VERSION ""

NS_ :

BS_:

BU_: VCU CIM BMS
VAL_TABLE_ KeyMatched 1 "Correct Key" 0 "Incorrect Key" ;
VAL_TABLE_ ClearFault 1 "Clear Fault Command" 0 "NA" ;

BO_ 274 BMS_HV_12: 8 BMS
 SG_ nBatteryHV12Multiplexor M : 0|3@1+ (1,0) [0|7] ""  VCU
 SG_ Batt_SerialNumber m1 : 56|8@1+ (1,0) [0|255] ""  VCU
 SG_ BMS_Calibration_info m0 : 32|8@1+ (1,0) [0|255] ""  VCU
 SG_ BMS_Software_info m0 : 24|8@1+ (1,0) [0|255] ""  VCU

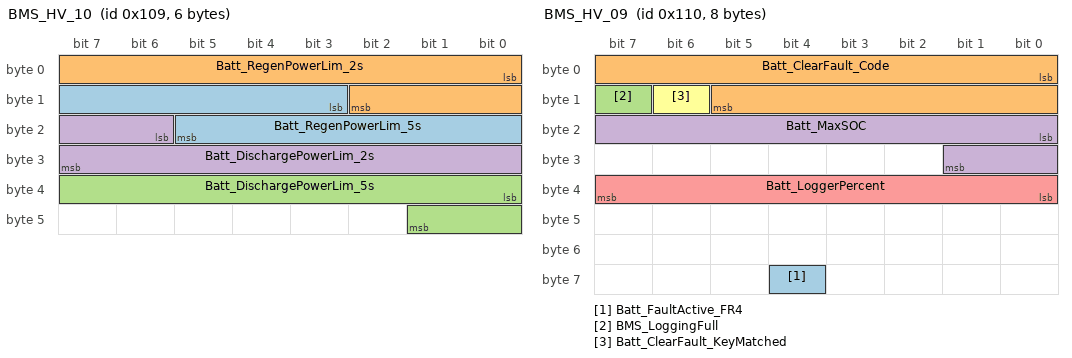
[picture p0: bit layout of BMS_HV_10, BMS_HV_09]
BO_ 265 BMS_HV_10: 6 BMS
 SG_ Batt_RegenPowerLim_5s : 11|11@1+ (0.5,0) [0|1023.5] "kW"  VCU
 SG_ Batt_RegenPowerLim_2s : 0|11@1+ (0.5,0) [0|1023.5] "kW"  VCU
 SG_ Batt_DischargePowerLim_5s : 32|10@1+ (0.5,-511.5) [-511.5|0] "kW"  VCU
 SG_ Batt_DischargePowerLim_2s : 22|10@1+ (0.5,-511.5) [-511.5|0] "kW"  VCU

BO_ 272 BMS_HV_09: 8 BMS
 SG_ Batt_FaultActive_FR4 : 60|1@1+ (1,0) [0|1] ""  VCU
 SG_ Batt_ClearFault_Code : 0|14@1+ (1,0) [0|9999] ""  VCU
 SG_ BMS_LoggingFull : 15|1@1+ (1,0) [0|1] ""  VCU
 SG_ Batt_MaxSOC : 16|10@1+ (0.1,0) [0|102.3] "%"  VCU
 SG_ Batt_LoggerPercent : 32|8@1+ (0.5,0) [0|127.5] "%"  VCU
 SG_ Batt_ClearFault_KeyMatched : 14|1@1+ (1,0) [0|1] ""  VCU

BO_ 264 VCM_FaultClearing: 8 VCU
 SG_ VCM_ClearBattFault_Key : 8|14@1+ (1,0) [0|9999] ""  BMS
 SG_ VCM_ClearBattFault_B : 0|1@1+ (1,0) [0|1] ""  BMS

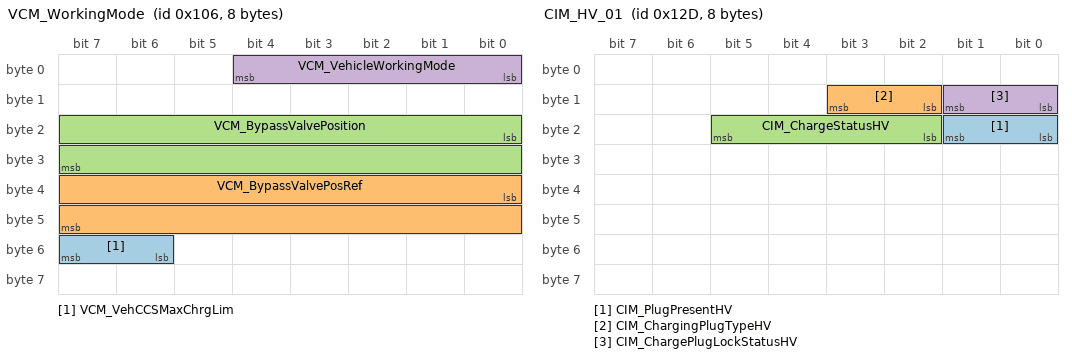
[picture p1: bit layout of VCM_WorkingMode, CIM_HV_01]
BO_ 262 VCM_WorkingMode: 8 VCU
 SG_ VCM_VehCCSMaxChrgLim : 54|2@1+ (1,0) [0|3] ""  BMS
 SG_ VCM_BypassValvePosRef : 32|16@1+ (0.1,0) [0|1000] "%"  BMS
 SG_ VCM_BypassValvePosition : 16|16@1+ (0.1,0) [0|1000] "%"  BMS
 SG_ VCM_VehicleWorkingMode : 0|5@1+ (1,0) [0|31] ""  BMS

BO_ 1537 BMS_CCP_TX: 8 BMS

BO_ 1536 BMS_CCP_RX: 8 BMS

BO_ 301 CIM_HV_01: 8 CIM
 SG_ CIM_PlugPresentHV : 16|2@1+ (1,0) [0|3] ""  BMS,VCU
 SG_ CIM_ChargingPlugTypeHV : 10|2@1+ (1,0) [0|3] ""  BMS,VCU
 SG_ CIM_ChargeStatusHV : 18|4@1+ (1,0) [0|15] ""  BMS,VCU
 SG_ CIM_ChargePlugLockStatusHV : 8|2@1+ (1,0) [0|3] ""  BMS,VCU

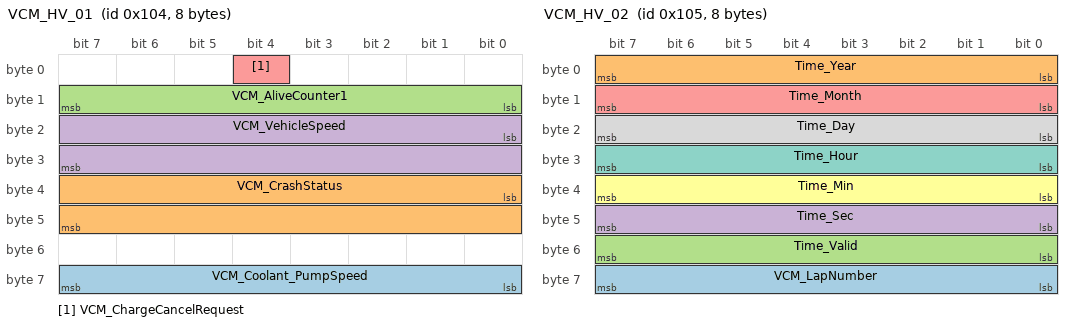
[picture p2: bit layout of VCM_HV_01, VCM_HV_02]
BO_ 260 VCM_HV_01: 8 VCU
 SG_ VCM_Coolant_PumpSpeed : 56|8@1+ (100,0) [0|25500] "RPM"  BMS
 SG_ VCM_CrashStatus : 32|16@1+ (1,0) [0|65535] ""  BMS
 SG_ VCM_AliveCounter1 : 8|8@1+ (1,0) [0|255] ""  BMS
 SG_ VCM_VehicleSpeed : 16|16@1+ (1,-32768) [-32768|32767] "kph"  BMS
 SG_ VCM_ChargeCancelRequest : 4|1@1+ (1,0) [0|1] ""  BMS

BO_ 261 VCM_HV_02: 8 VCU
 SG_ VCM_LapNumber : 56|8@1+ (1,0) [0|255] ""  BMS
 SG_ Time_Year : 0|8@1+ (1,0) [0|255] "min"  BMS
 SG_ Time_Valid : 48|8@1+ (1,0) [0|255] "min"  BMS
 SG_ Time_Sec : 40|8@1+ (1,0) [0|255] "min"  BMS
 SG_ Time_Month : 8|8@1+ (1,0) [0|255] "min"  BMS
 SG_ Time_Min : 32|8@1+ (1,0) [0|255] "min"  BMS
 SG_ Time_Hour : 24|8@1+ (1,0) [0|255] "min"  BMS
 SG_ Time_Day : 16|8@1+ (1,0) [0|255] "min"  BMS

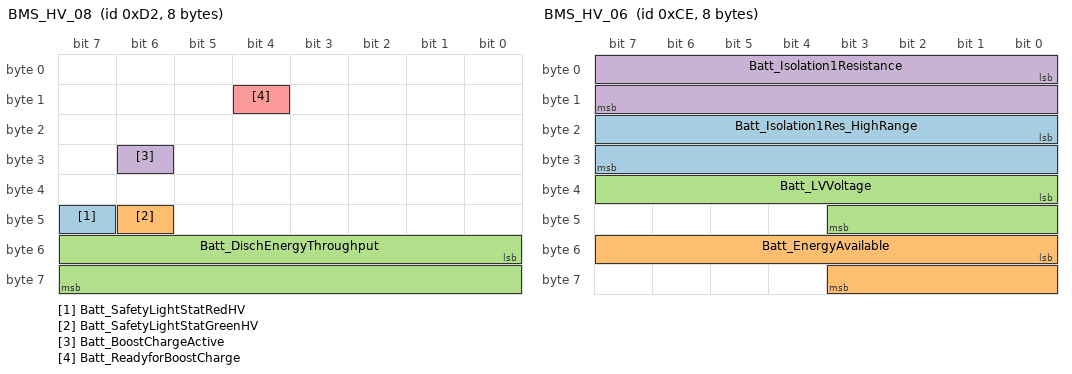
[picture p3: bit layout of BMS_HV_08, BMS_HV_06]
BO_ 210 BMS_HV_08: 8 BMS
 SG_ Batt_SafetyLightStatRedHV : 47|1@1+ (1,0) [0|1] ""  VCU
 SG_ Batt_SafetyLightStatGreenHV : 46|1@1+ (1,0) [0|1] ""  VCU
 SG_ Batt_DischEnergyThroughput : 48|16@1+ (0.5,0) [0|32767.5] "kWh"  VCU
 SG_ Batt_BoostChargeActive : 30|1@1+ (1,0) [0|1] ""  VCU
 SG_ Batt_ReadyforBoostCharge : 12|1@1+ (1,0) [0|1] ""  VCU

BO_ 206 BMS_HV_06: 8 BMS
 SG_ Batt_Isolation1Res_HighRange : 16|16@1+ (1,0) [0|65535] "kOhm"  VCU
 SG_ Batt_EnergyAvailable : 48|12@1+ (0.1,0) [0|409.5] "kWh"  VCU
 SG_ Batt_LVVoltage : 32|12@1+ (0.01,0) [0|40.95] "V"  VCU
 SG_ Batt_Isolation1Resistance : 0|16@1+ (0.1,0) [0|6553.5] "kOhm"  VCU

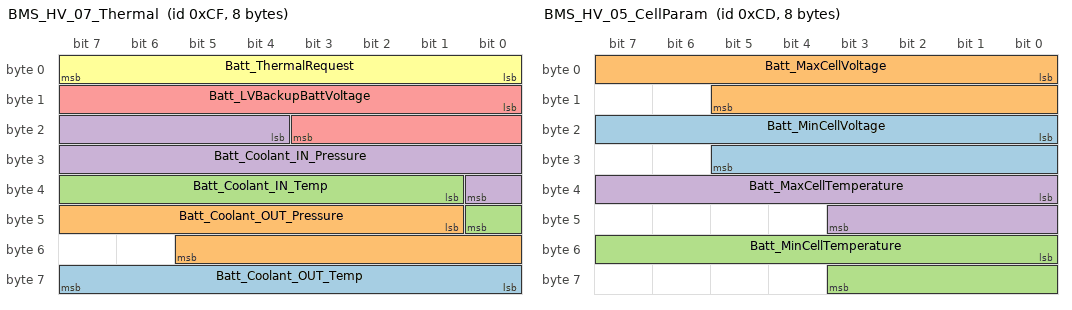
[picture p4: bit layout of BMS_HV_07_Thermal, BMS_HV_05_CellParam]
BO_ 207 BMS_HV_07_Thermal: 8 BMS
 SG_ Batt_Coolant_OUT_Temp : 56|8@1+ (0.5,-20) [-10|117.5] "C"  VCU
 SG_ Batt_Coolant_OUT_Pressure : 41|13@1+ (0.001,0) [0|8.191] "Bar"  VCU
 SG_ Batt_Coolant_IN_Temp : 33|8@1+ (0.5,-20) [-10|117.5] "C"  VCU
 SG_ Batt_Coolant_IN_Pressure : 20|13@1+ (0.001,0) [0|8.191] "Bar"  VCU
 SG_ Batt_LVBackupBattVoltage : 8|12@1+ (0.01,0) [0|40.95] "V"  VCU
 SG_ Batt_ThermalRequest : 0|8@1+ (1,-128) [-128|127] ""  VCU

BO_ 205 BMS_HV_05_CellParam: 8 BMS
 SG_ Batt_MinCellVoltage : 16|14@1+ (0.001,0) [0|16.383] "V"  VCU
 SG_ Batt_MaxCellVoltage : 0|14@1+ (0.001,0) [0|16.383] "V"  VCU
 SG_ Batt_MinCellTemperature : 48|12@1+ (0.05,-60) [-60|144.75] "C"  VCU
 SG_ Batt_MaxCellTemperature : 32|12@1+ (0.05,-60) [-60|144.75] "C"  VCU

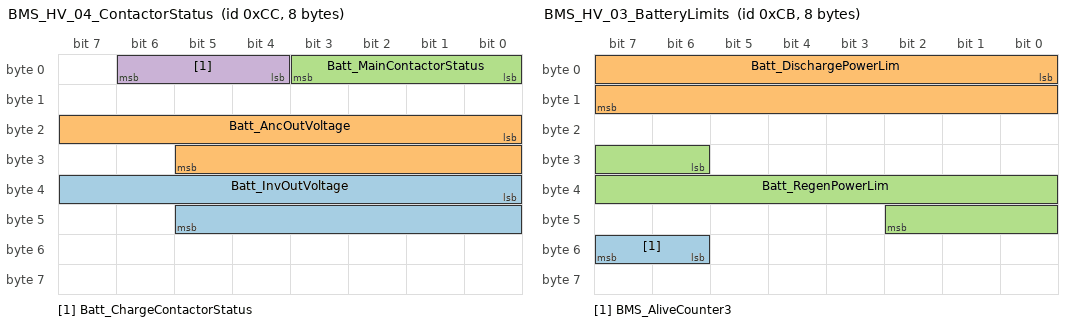
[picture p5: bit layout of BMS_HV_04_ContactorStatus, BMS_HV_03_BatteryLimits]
BO_ 204 BMS_HV_04_ContactorStatus: 8 BMS
 SG_ Batt_InvOutVoltage : 32|14@1+ (0.1,0) [0|1638.3] "V"  VCU
 SG_ Batt_AncOutVoltage : 16|14@1+ (0.1,0) [0|1638.3] "V"  VCU
 SG_ Batt_MainContactorStatus : 0|4@1+ (1,0) [0|15] ""  VCU
 SG_ Batt_ChargeContactorStatus : 4|3@1+ (1,0) [0|7] ""  VCU

BO_ 203 BMS_HV_03_BatteryLimits: 8 BMS
 SG_ BMS_AliveCounter3 : 54|2@1+ (1,0) [0|3] ""  VCU
 SG_ Batt_DischargePowerLim : 0|16@1+ (0.05,-3276.75) [-3276.75|0] "kW"  VCU
 SG_ Batt_RegenPowerLim : 30|13@1+ (0.1,0) [0|819.1] "kW"  VCU

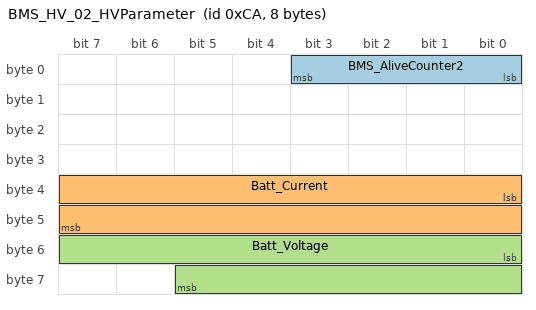
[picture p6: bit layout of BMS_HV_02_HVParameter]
BO_ 202 BMS_HV_02_HVParameter: 8 BMS
 SG_ BMS_AliveCounter2 : 0|4@1+ (1,0) [0|15] ""  VCU
 SG_ Batt_Current : 32|16@1+ (0.1,-3276.8) [-3276.8|3276.7] "A"  VCU
 SG_ Batt_Voltage : 48|14@1+ (0.1,0) [0|1638.3] "V"  VCU

BO_ 201 BMS_HV_01_Status: 8 BMS
 SG_ Batt_Equity_SoC_Displayed : 9|1@1+ (1,0) [0|1] ""  VCU
 SG_ BMS_AliveCounter1 : 26|4@1+ (1,0) [0|15] ""  VCU
 SG_ Batt_UserSOC : 32|10@1+ (0.1,0) [0|102.3] "%"  VCU
 SG_ Batt_MinSOC : 16|10@1+ (0.1,0) [0|102.3] "%"  VCU
 SG_ Batt_ReadytoTurnOnHV : 0|1@1+ (1,0) [0|1] ""  VCU
 SG_ Batt_BMSStatus : 48|5@1+ (1,0) [0|31] ""  VCU
 SG_ Batt_Isolation2Status : 14|2@1+ (1,0) [0|3] ""  VCU
 SG_ Batt_Isolation1Status : 42|2@1+ (1,0) [0|3] ""  VCU
 SG_ Batt_HVILFault : 30|2@1+ (1,0) [0|3] ""  VCU
 SG_ Batt_Isolation2OnOffStatus : 13|1@1+ (1,0) [0|1] ""  VCU
 SG_ Batt_Isolation1OnOffStatus : 12|1@1+ (1,0) [0|1] ""  VCU
 SG_ Batt_BalancingRequired : 10|1@1+ (1,0) [0|1] ""  VCU
 SG_ Batt_Fault_FR7 : 8|1@1+ (1,0) [0|1] ""  VCU
 SG_ Batt_Fault_FR6 : 7|1@1+ (1,0) [0|1] ""  VCU
 SG_ Batt_Fault_FR5 : 6|1@1+ (1,0) [0|1] ""  VCU
 SG_ Batt_Fault_FR4 : 5|1@1+ (1,0) [0|1] ""  VCU
 SG_ Batt_Fault_FR3 : 4|1@1+ (1,0) [0|1] ""  VCU
 SG_ Batt_Fault_FR2 : 3|1@1+ (1,0) [0|1] ""  VCU
 SG_ Batt_Fault_FR1 : 2|1@1+ (1,0) [0|1] ""  VCU
 SG_ Batt_Fault_FR0 : 1|1@1+ (1,0) [0|1] ""  VCU

BO_TX_BU_ 301 : BMS,CIM;

CM_ BU_ CIM "Charge Interface Module";
CM_ BU_ BMS "Battery Management System";
CM_ SG_ 274 Batt_SerialNumber "Batt_SerialNumber";
CM_ SG_ 274 BMS_Calibration_info "BMS_Calibration_information";
CM_ SG_ 274 BMS_Software_info "BMS_Software_information";
CM_ SG_ 265 Batt_RegenPowerLim_5s "Battery Power Limit";
CM_ SG_ 265 Batt_RegenPowerLim_2s "Battery Power Limit";
CM_ SG_ 265 Batt_DischargePowerLim_5s "Battery Power Limit";
CM_ SG_ 265 Batt_DischargePowerLim_2s "Battery Power Limit";
CM_ SG_ 272 Batt_FaultActive_FR4 "BMS Fault Flag";
CM_ SG_ 272 Batt_ClearFault_Code "Number generate by BMS to clear fault";
CM_ SG_ 272 BMS_LoggingFull "BMS logger status full";
CM_ SG_ 272 Batt_MaxSOC "Battery Maximum SoC";
CM_ SG_ 272 Batt_LoggerPercent "BMS Logger Percentage";
CM_ SG_ 272 Batt_ClearFault_KeyMatched "Key matched to clear the fault";
CM_ SG_ 264 VCM_ClearBattFault_Key "Key for clearing latch fault on BMS";
CM_ SG_ 264 VCM_ClearBattFault_B "Boolean singal to clear latch fault";
CM_ SG_ 262 VCM_VehCCSMaxChrgLim "CCS charge max power limit if charger used with lower supply.
Can't be changed mid charge.";
CM_ SG_ 262 VCM_BypassValvePosRef "RESS SOBEK Coolant valve position reference forwarded from VehicleECU from SOBEK CAN message 0x365. 
Must be the same signal forwarded, strictly identical as sent to SOBEK Coolant valve";
CM_ SG_ 262 VCM_BypassValvePosition "RESS SOBEK Coolant valve position feedback forwarded from VehicleECU from SOBEK CAN message 0x375. 
Must be the same signal forwarded, strictly identical as received by SOBEK valve";
CM_ SG_ 262 VCM_VehicleWorkingMode "VCM Working Mode";
CM_ SG_ 301 CIM_PlugPresentHV "Plug preset acknowledgement";
CM_ SG_ 301 CIM_ChargingPlugTypeHV "Charge Plug Type";
CM_ SG_ 301 CIM_ChargeStatusHV "Charge Status";
CM_ SG_ 301 CIM_ChargePlugLockStatusHV "Charge Plug Lock Status";
CM_ SG_ 260 VCM_Coolant_PumpSpeed "RESS SOBEK Coolant Pump Speed feedback forwarded from VehicleECU from SOBEK CAN message 0x371.";
CM_ SG_ 260 VCM_CrashStatus "Crash Signal from VehicleECU. A non zero value will trigger crash and open contactors";
CM_ SG_ 260 VCM_AliveCounter1 "VCM Alive Counter";
CM_ SG_ 260 VCM_VehicleSpeed "Vehicle Speed";
CM_ SG_ 260 VCM_ChargeCancelRequest "VCM Request to stop Charging";
CM_ SG_ 261 Time_Valid "Validity flags ";
CM_ SG_ 210 Batt_SafetyLightStatRedHV "Bttery safety light status RED";
CM_ SG_ 210 Batt_SafetyLightStatGreenHV "Bttery safety light status Green";
CM_ SG_ 210 Batt_DischEnergyThroughput "Discharge Energy Throughput";
CM_ SG_ 210 Batt_BoostChargeActive "Boost charge active flag";
CM_ SG_ 210 Batt_ReadyforBoostCharge "Battery Ready for Boost Charge";
CM_ SG_ 206 Batt_Isolation1Res_HighRange "Isolation Resistance Value";
CM_ SG_ 206 Batt_EnergyAvailable "Battery Energy Available";
CM_ SG_ 206 Batt_LVVoltage "LV(KL30) supply Voltage";
CM_ SG_ 206 Batt_Isolation1Resistance "Isolation Resistance Value";
CM_ SG_ 207 Batt_Coolant_OUT_Temp "Coolant Temperature";
CM_ SG_ 207 Batt_Coolant_OUT_Pressure "Coolant Pressure";
CM_ SG_ 207 Batt_Coolant_IN_Temp "Coolant Temperature";
CM_ SG_ 207 Batt_Coolant_IN_Pressure "Coolant Pressure";
CM_ SG_ 207 Batt_LVBackupBattVoltage "LV(KL30) supply Voltage";
CM_ SG_ 207 Batt_ThermalRequest "BMS Thermal Request
Negative= Cooling Request
Positive= Heating Request";
CM_ SG_ 205 Batt_MinCellVoltage "Module Minimum Cell Voltage";
CM_ SG_ 205 Batt_MaxCellVoltage "Module Maximum Cell Voltage";
CM_ SG_ 205 Batt_MinCellTemperature "Minimum Module Temperature";
CM_ SG_ 205 Batt_MaxCellTemperature "Maximum Module Temperature";
CM_ SG_ 204 Batt_InvOutVoltage "HV Bus Voltage- Inverter Output";
CM_ SG_ 204 Batt_AncOutVoltage "HV Bus Voltage- Ancillary Output";
CM_ SG_ 204 Batt_MainContactorStatus " Main Contactor Status";
CM_ SG_ 204 Batt_ChargeContactorStatus "Charge contactor status";
CM_ SG_ 203 BMS_AliveCounter3 "BMS Alive Counter";
CM_ SG_ 203 Batt_DischargePowerLim "Battery Power Limit";
CM_ SG_ 203 Batt_RegenPowerLim "Battery Power Limit";
CM_ SG_ 202 BMS_AliveCounter2 "BMS Alive Counter";
CM_ SG_ 202 Batt_Current "Battery Current
Negative Value= Discharge Current
Positive Value= Regen/Charge Current";
CM_ SG_ 202 Batt_Voltage "Battery Voltage";
CM_ SG_ 201 Batt_Equity_SoC_Displayed "BMS Equity SoC displayed";
CM_ SG_ 201 BMS_AliveCounter1 "BMS Alive Counter";
CM_ SG_ 201 Batt_UserSOC "Battery User SoC (for Display Purpose)";
CM_ SG_ 201 Batt_MinSOC "Battery Minimum SoC";
CM_ SG_ 201 Batt_ReadytoTurnOnHV "BMS Ready to close HV Contactors";
CM_ SG_ 201 Batt_BMSStatus "BMS Status";
CM_ SG_ 201 Batt_Isolation2Status "Battery Isolation Status";
CM_ SG_ 201 Batt_Isolation1Status "Battery Isolation Status";
CM_ SG_ 201 Batt_HVILFault "Battery HVIL Status";
CM_ SG_ 201 Batt_Isolation2OnOffStatus "Isolation Enable/Disable Status";
CM_ SG_ 201 Batt_Isolation1OnOffStatus "Isolation Enable/Disable Status";
CM_ SG_ 201 Batt_BalancingRequired "Battery Cell balancing required";
CM_ SG_ 201 Batt_Fault_FR7 "BMS Fault Flag";
CM_ SG_ 201 Batt_Fault_FR6 "BMS Fault Flag";
CM_ SG_ 201 Batt_Fault_FR5 "BMS Fault Flag";
CM_ SG_ 201 Batt_Fault_FR4 "BMS Fault Flag";
CM_ SG_ 201 Batt_Fault_FR3 "BMS Fault Flag";
CM_ SG_ 201 Batt_Fault_FR2 "BMS Fault Flag";
CM_ SG_ 201 Batt_Fault_FR1 "BMS Fault Flag";
CM_ SG_ 201 Batt_Fault_FR0 "BMS Fault Flag";
BA_DEF_  "BusType" STRING ;
BA_DEF_  "DBName" STRING ;
BA_DEF_  "Baudrate" FLOAT 0 1000000;
BA_DEF_ BO_  "GenMsgILSupport" ENUM  "No","Yes";
BA_DEF_ BO_  "GenMsgCycleTime" INT 0 10000;
BA_DEF_ BO_  "GenMsgSendType" ENUM  "Cyclic","Spontaneous","NotUsed","NotUsed","NotUsed","NotUsed","NotUsed","IfActive","NoMsgSendType","NotUsed";
BA_DEF_ BU_  "ILUsed" ENUM  "No","Yes";
BA_DEF_ BU_  "NodeLayerModules" STRING ;
BA_DEF_DEF_  "BusType" "";
BA_DEF_DEF_  "DBName" "";
BA_DEF_DEF_  "Baudrate" 500000;
BA_DEF_DEF_  "GenMsgILSupport" "Yes";
BA_DEF_DEF_  "GenMsgCycleTime" 10;
BA_DEF_DEF_  "GenMsgSendType" "Cyclic";
BA_DEF_DEF_  "ILUsed" "Yes";
BA_DEF_DEF_  "NodeLayerModules" "CANoeILNLDefault.dll";
BA_ "Baudrate" 1000000;
BA_ "BusType" "CAN";
BA_ "DBName" "BMSv19";
BA_ "GenMsgCycleTime" BO_ 274 1000;
BA_ "GenMsgCycleTime" BO_ 265 20;
BA_ "GenMsgCycleTime" BO_ 272 200;
BA_ "GenMsgCycleTime" BO_ 264 200;
BA_ "GenMsgCycleTime" BO_ 301 200;
BA_ "GenMsgCycleTime" BO_ 261 500;
BA_ "GenMsgCycleTime" BO_ 210 200;
BA_ "GenMsgCycleTime" BO_ 206 200;
BA_ "GenMsgCycleTime" BO_ 207 200;
BA_ "GenMsgCycleTime" BO_ 205 200;
BA_ "GenMsgCycleTime" BO_ 204 100;
BA_ "GenMsgCycleTime" BO_ 203 20;
BA_ "GenMsgCycleTime" BO_ 202 20;
BA_ "GenMsgCycleTime" BO_ 201 50;
VAL_ 272 Batt_FaultActive_FR4 1 "Fault" 0 "No Fault" ;
VAL_ 272 BMS_LoggingFull 1 "True" 0 "False" ;
VAL_ 272 Batt_ClearFault_KeyMatched 1 "Correct Key" 0 "Incorrect Key" ;
VAL_ 262 VCM_VehCCSMaxChrgLim 2 "32A Supply Lim" 1 "63A Supply Lim" 0 "125A Supply Lim" ;
VAL_ 262 VCM_VehicleWorkingMode 9 "RaceCharge" 8 "DischargeForTransport" 7 "ReadyToDrive" 6 "HVOn" 5 "N/A" 4 "HVCharge" 3 "HVChargePrep" 2 "N/A" 1 "LVOn" 0 "OFF" ;
VAL_ 301 CIM_PlugPresentHV 1 "Plug present" 0 "No plug present" ;
VAL_ 301 CIM_ChargingPlugTypeHV 3 "Discharge for Transport" 2 "CCS2 Charge" 1 "RACE Charge" 0 "No plug detected" ;
VAL_ 301 CIM_ChargeStatusHV 4 "Discharge for Transport" 3 "Charge finished" 2 "Charge in progress" 1 "Initialising" 0 "Off" ;
VAL_ 301 CIM_ChargePlugLockStatusHV 3 "Error" 2 "Plug connected - Fault" 1 "Plug connected - OK" 0 "No plug detected" ;
VAL_ 260 VCM_ChargeCancelRequest 1 "True" 0 "False" ;
VAL_ 261 Time_Valid 4 "Leap valid" 3 "NOT USED" 2 "Week valid " 1 "Time of Week valid " 0 "NOT USED" ;
VAL_ 210 Batt_SafetyLightStatRedHV 1 "On" 0 "Off" ;
VAL_ 210 Batt_SafetyLightStatGreenHV 1 "On" 0 "Off" ;
VAL_ 210 Batt_BoostChargeActive 1 "True" 0 "False" ;
VAL_ 210 Batt_ReadyforBoostCharge 1 "True" 0 "False" ;
VAL_ 204 Batt_MainContactorStatus 7 "MainPosC_AncNegC_InvNegC" 6 "MainPosO_AncNegC_InvNegC" 5 "MainPosC_AncNegO_InvNegC" 4 "MainPosO_AncNegO_InvNegC" 3 "MainPosC_AncNegC_InvNegO" 2 "MainPosO_AncNegC_InvNegO" 1 "MainPosC_AncNegO_InvNegO" 0 "MainPosO_AncNegO_InvNegO" ;
VAL_ 204 Batt_ChargeContactorStatus 3 "PosC NegC" 2 "PosO NegC" 1 "PosC NegO" 0 "PosO NegO" ;
VAL_ 201 Batt_Equity_SoC_Displayed 1 "Equity SoC" 0 "Real SoC" ;
VAL_ 201 Batt_ReadytoTurnOnHV 1 "True" 0 "False" ;
VAL_ 201 Batt_BMSStatus 14 "Discharge Transport" 13 "Inverters Powered" 12 "Inverters Precharge" 11 "Bus Discharging" 10 "Self Wake" 9 "Fault Mode" 8 "Shutting Down" 7 "CCS2 Charge" 6 "Race Charge" 5 "Charge Prep" 4 "Ancillaries Powered" 3 "Ancillaries Precharge" 2 "Standby" 1 "Initialising" 0 "Off" ;
VAL_ 201 Batt_Isolation2Status 3 "Device Fault" 2 "Fault" 1 "No Fault" 0 "Measuring" ;
VAL_ 201 Batt_Isolation1Status 3 "Device Fault" 2 "Fault" 1 "No Fault" 0 "Measuring" ;
VAL_ 201 Batt_HVILFault 3 "Device Fault" 2 "Open" 1 "Closed" 0 "Measuring" ;
VAL_ 201 Batt_Isolation2OnOffStatus 1 "Isolation Monitoring ON" 0 "Isolation Monitoring OFF" ;
VAL_ 201 Batt_Isolation1OnOffStatus 1 "Isolation Monitoring ON" 0 "Isolation Monitoring OFF" ;
VAL_ 201 Batt_BalancingRequired 1 "True" 0 "False" ;
VAL_ 201 Batt_Fault_FR7 1 "Fault" 0 "No Fault" ;
VAL_ 201 Batt_Fault_FR6 1 "Fault" 0 "No Fault" ;
VAL_ 201 Batt_Fault_FR5 1 "Fault" 0 "No Fault" ;
VAL_ 201 Batt_Fault_FR4 1 "Fault" 0 "No Fault" ;
VAL_ 201 Batt_Fault_FR3 1 "Fault" 0 "No Fault" ;
VAL_ 201 Batt_Fault_FR2 1 "Fault" 0 "No Fault" ;
VAL_ 201 Batt_Fault_FR1 1 "Fault" 0 "No Fault" ;
VAL_ 201 Batt_Fault_FR0 1 "Fault" 0 "No Fault" ;
